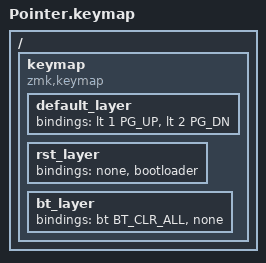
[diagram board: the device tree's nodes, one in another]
#include <behaviors.dtsi>
#include <dt-bindings/zmk/keys.h>
#include <dt-bindings/zmk/bt.h>

/ {
    keymap {
        compatible = "zmk,keymap";

        default_layer {
            bindings = < 
            &lt 1 PG_UP
            &lt 2 PG_DN
            >;
        };

        rst_layer {
            bindings = < 
            &none
            &bootloader
            >;
        };

        bt_layer {
            bindings = < 
            &bt BT_CLR_ALL
            &none
            >;
        };
    };
 };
